# MKE15Z4 register map
Vendor: nxp.com; File version: 1.0
CPU: CM0PLUS r0p0, little endian, no MPU, no FPU, VTOR, 2 interrupt priority bits
Registers are 32-bit, read-write, reset 0x0 unless marked. A register's access mark holds for its fields unless they carry their own. Offsets are from the block's base; [hi:lo] are bit positions; {n}, {i} and the like mark numbered series; 'fields as' and 'values as' point back to an identical list.

## PORTA — Pin Control and Interrupts
Base 0x40049000; register names take the prefix PORTA_
Same registers: PORTB 0x4004A000 (register names take the prefix PORTB_), PORTC 0x4004B000 (register names take the prefix PORTC_), PORTD 0x4004C000 (register names take the prefix PORTD_), PORTE 0x4004D000 (register names take the prefix PORTE_)
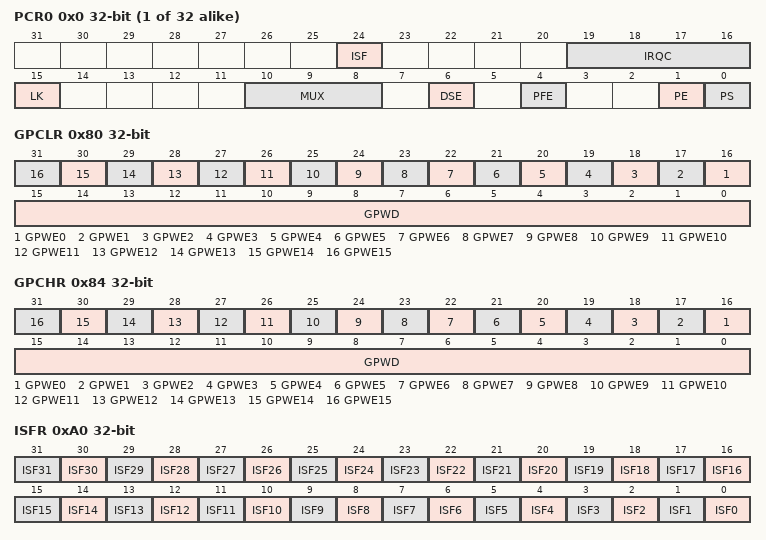
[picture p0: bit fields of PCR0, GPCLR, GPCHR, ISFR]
{0x0+4i} PCR{i} (i=0..31) — Pin Control Register n
  [24] ISF write-1-clears — Interrupt Status Flag
    0=NOT_DETECTED (Configured interrupt is not detected.); 1=DETECTED (Configured interrupt is detected. The flag remains set until a logic 1 is written to the flag. If the pin is configured for a level sensitive interrupt and the pin remains asserted, then the flag is set again immediately after it is cleared.)
  [19:16] IRQC — Interrupt Configuration
    0=DISABLED (Interrupt Status Flag (ISF) is disabled.); 8=INT_ZERO (ISF flag and Interrupt when logic 0.); 9=INT_RISING (ISF flag and Interrupt on rising-edge.); 10=INT_FALLING (ISF flag and Interrupt on falling-edge.); 11=INT_BOTH (ISF flag and Interrupt on either edge.); 12=INT_ONE (ISF flag and Interrupt when logic 1.)
  [15] LK — Lock Register
    0=NOT_LOCKED (Pin Control Register fields [15:0] are not locked.); 1=LOCKED (Pin Control Register fields [15:0] are locked and cannot be updated until the next system reset.)
  [10:8] MUX — Pin Mux Control
    0=ANA_DIS (Pin disabled (Alternative 0) (analog).); 1=GPIO (Alternative 1 (GPIO).); {v}=ALT{v} (Alternative {v} (chip-specific).) (v=2..7)
  [6] DSE ro — Drive Strength Enable
    0=LOW (Low drive strength is configured on the corresponding pin, if pin is configured as a digital output.); 1=HIGH (High drive strength is configured on the corresponding pin, if pin is configured as a digital output.)
  [4] PFE ro — Passive Filter Enable
    0=DISABLED (Passive input filter is disabled on the corresponding pin.); 1=ENABLED (Passive input filter is enabled on the corresponding pin, if the pin is configured as a digital input. Refer to the device data sheet for filter characteristics.)
  [1] PE — Pull Enable
    0=DISABLED (Internal pullup or pulldown resistor is not enabled on the corresponding pin.); 1=ENABLED (Internal pullup or pulldown resistor is enabled on the corresponding pin, if the pin is configured as a digital input.)
  [0] PS — Pull Select
    0=DOWN (Internal pulldown resistor is enabled on the corresponding pin, if the corresponding PE field is set.); 1=UP (Internal pullup resistor is enabled on the corresponding pin, if the corresponding PE field is set.)
0x80 GPCLR — Global Pin Control Low Register
  [n+16] GPWE{n} (n=0..15) — Global Pin Write Enable
    0=GPWE_0 (Corresponding Pin Control Register is not updated with the value in GPWD.); 1=GPWE_1 (Corresponding Pin Control Register is updated with the value in GPWD.)
  [15:0] GPWD — Global Pin Write Data
0x84 GPCHR — Global Pin Control High Register
  fields as GPCLR
0xA0 ISFR — Interrupt Status Flag Register
  [all] fields
    values as PCR0.ISF
  [n] ISF{n} write-1-clears (n=0..31) — Interrupt Status Flag
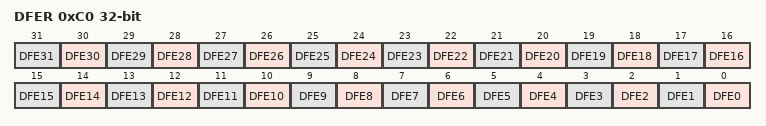
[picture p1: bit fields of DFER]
0xC0 DFER — Digital Filter Enable Register
  [all] fields
    0=DISABLED (Digital filter is disabled on the corresponding pin and output of the digital filter is reset to zero.); 1=ENABLED (Digital filter is enabled on the corresponding pin, if the pin is configured as a digital input.)
  [n] DFE{n} (n=0..31) — Digital Filter Enable
0xC4 DFCR — Digital Filter Clock Register
  [0] CS — Clock Source
    0=BUS (Digital filters are clocked by the bus clock.); 1=LPO (Digital filters are clocked by the LPO clock.)
0xC8 DFWR — Digital Filter Width Register
  [4:0] FILT — Filter Length
